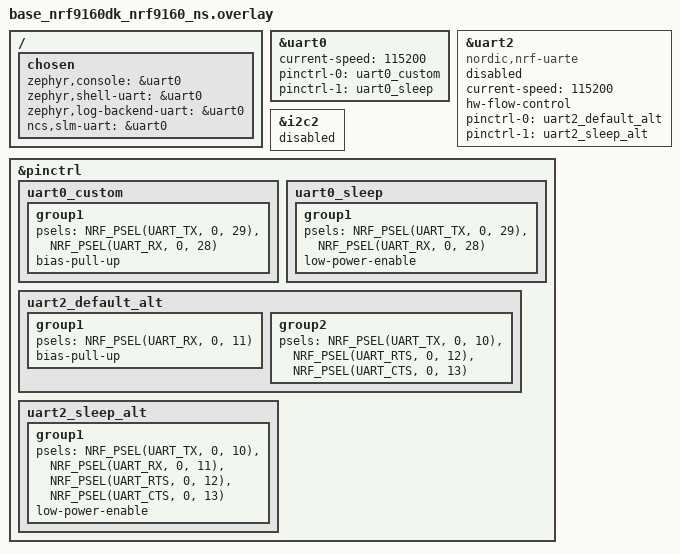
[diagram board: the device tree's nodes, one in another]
/*
 * Copyright (c) 2021 Nordic Semiconductor ASA
 *
 * SPDX-License-Identifier: LicenseRef-Nordic-5-Clause
 */

/ {
	chosen {
		zephyr,console = &uart0;
		zephyr,shell-uart = &uart0;
		zephyr,log-backend-uart = &uart0;
		ncs,slm-uart = &uart0;
	};
};

&uart0 {
	status = "okay";
	current-speed = <115200>;
	// hw-flow-control;
	pinctrl-0 = <&uart0_custom>;
	pinctrl-1 = <&uart0_sleep>;
	pinctrl-names = "default", "sleep";
};

&uart2 {
	compatible = "nordic,nrf-uarte";
	current-speed = <115200>;
	status = "disabled";
	hw-flow-control;

	pinctrl-0 = <&uart2_default_alt>;
	pinctrl-1 = <&uart2_sleep_alt>;
	pinctrl-names = "default", "sleep";
};

&i2c2 {
	status = "disabled";
};

&pinctrl {
	uart0_custom: uart0_custom {
		group1 {
			psels = <NRF_PSEL(UART_TX, 0, 29)>, 
					<NRF_PSEL(UART_RX, 0, 28)>;
			bias-pull-up;
		};
	};

	uart0_sleep: uart0_sleep {
		group1 {
			psels = <NRF_PSEL(UART_TX, 0, 29)>,
			        <NRF_PSEL(UART_RX, 0, 28)>;
			low-power-enable;
		};
	};

	uart2_default_alt: uart2_default_alt {
		group1 {
			psels = <NRF_PSEL(UART_RX, 0, 11)>;
			bias-pull-up;
		};
		group2 {
			psels = <NRF_PSEL(UART_TX, 0, 10)>,
				<NRF_PSEL(UART_RTS, 0, 12)>,
				<NRF_PSEL(UART_CTS, 0, 13)>;
		};
	};

	uart2_sleep_alt: uart2_sleep_alt {
		group1 {
			psels = <NRF_PSEL(UART_TX, 0, 10)>,
				<NRF_PSEL(UART_RX, 0, 11)>,
				<NRF_PSEL(UART_RTS, 0, 12)>,
				<NRF_PSEL(UART_CTS, 0, 13)>;
			low-power-enable;
		};
	};
};
